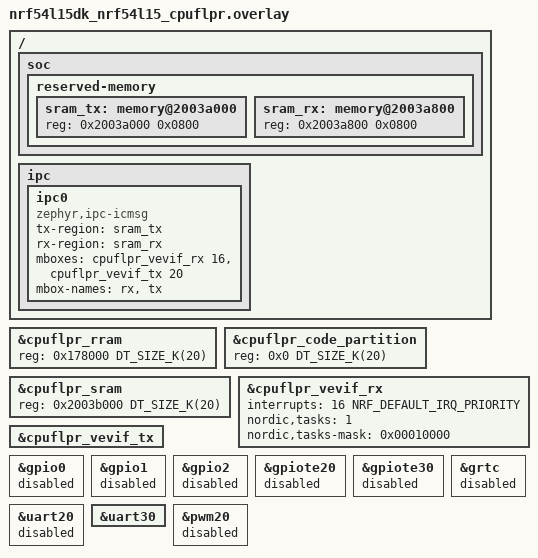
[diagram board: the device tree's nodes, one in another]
/*
 * Copyright (c) 2024 Nordic Semiconductor ASA
 *
 * SPDX-License-Identifier: LicenseRef-Nordic-5-Clause
 */

/ {
	soc {
		reserved-memory {
			#address-cells = <1>;
			#size-cells = <1>;

			sram_tx: memory@2003a000 {
				reg = <0x2003a000 0x0800>;
			};

			sram_rx: memory@2003a800 {
				reg = <0x2003a800 0x0800>;
			};
		};
	};

	ipc {
		ipc0: ipc0 {
			compatible = "zephyr,ipc-icmsg";
			tx-region = <&sram_tx>;
			rx-region = <&sram_rx>;
			mboxes = <&cpuflpr_vevif_rx 16>, <&cpuflpr_vevif_tx 20>;
			mbox-names = "rx", "tx";
			status = "okay";
		};
	};
};

&cpuflpr_rram {
	reg = <0x178000 DT_SIZE_K(20)>;
};

&cpuflpr_code_partition {
	reg = <0x0 DT_SIZE_K(20)>;
};

&cpuflpr_sram {
	reg = <0x2003b000 DT_SIZE_K(20)>;
	ranges = <0x0 0x2003b000 0x5000>;
};

&cpuflpr_vevif_rx {
	status = "okay";
	interrupts = <16 NRF_DEFAULT_IRQ_PRIORITY>;
	nordic,tasks = <1>;
	nordic,tasks-mask = <0x00010000>;
};

&cpuflpr_vevif_tx {
	status = "okay";
};

&gpio0 {
	status = "disabled";
};

&gpio1 {
	status = "disabled";
};

&gpio2 {
	status = "disabled";
};

&gpiote20 {
	status = "disabled";
};

&gpiote30 {
	status = "disabled";
};

&grtc {
	status = "disabled";
};

&uart20 {
	status = "disabled";
};

&uart30 {
	status = "okay";
};

&pwm20 {
	status = "disabled";
};
